AUTOSAR XML (schema 4-2-2)
package /Asw
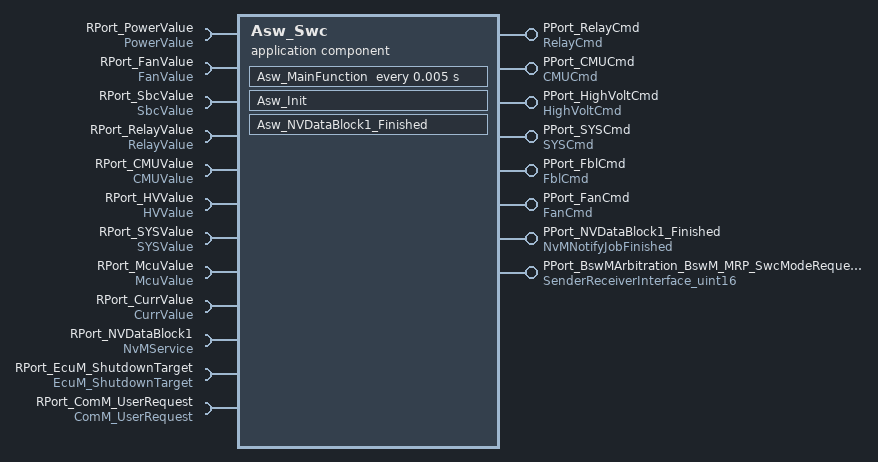
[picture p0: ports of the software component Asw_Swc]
  application sw component type Asw_Swc
    5 x provide port:
      PPort_RelayCmd: provided-interface=RelayCmd
      PPort_CMUCmd: provided-interface=CMUCmd
      PPort_HighVoltCmd: provided-interface=HighVoltCmd
      PPort_SYSCmd: provided-interface=SYSCmd
      PPort_FblCmd: provided-interface=FblCmd
    9 x require port:
      RPort_PowerValue: required-interface=PowerValue
      RPort_FanValue: required-interface=FanValue
      RPort_SbcValue: required-interface=SbcValue
      RPort_RelayValue: required-interface=RelayValue
      RPort_CMUValue: required-interface=CMUValue
      RPort_HVValue: required-interface=HVValue
      RPort_SYSValue: required-interface=SYSValue
      RPort_McuValue: required-interface=McuValue
      RPort_CurrValue: required-interface=CurrValue
    provide port PPort_FanCmd: provided-interface=FanCmd
    provide port PPort_NVDataBlock1_Finished: provided-interface=NvMNotifyJobFinished
    require port RPort_NVDataBlock1: required-interface=NvMService
    provide port PPort_BswMArbitration_BswM_MRP_SwcModeRequest: provided-interface=SenderReceiverInterface_uint16
    require port RPort_EcuM_ShutdownTarget: required-interface=EcuM_ShutdownTarget
    require port RPort_ComM_UserRequest: required-interface=ComM_UserRequest
    behavior SwcInternalBehavior: data-type-mapping=ComMModeMapping
      timing event TE_Asw_MainFunction_5ms: start-on-event=Asw_MainFunction, period=0.005
      operation invoked event OE_Asw_NVDataBlock1_Finished: start-on-event=Asw_NVDataBlock1_Finished, operation=PPort_NVDataBlock1_Finished.JobFinished
      runnable Asw_MainFunction
        data-receive-point-by-arguments:
          31 x access:
            DRPA_KL30Volt_V_0: accessed-variable=RPort_PowerValue.KL30Volt_V
            DRPA_KL30VoltVld_flg_0: accessed-variable=RPort_PowerValue.KL30VoltVld_flg
            DRPA_BSWInitFinish_flg_0: accessed-variable=RPort_McuValue.BSWInitFinish_flg
            DRPA_KL15WakeupState_flg_0: accessed-variable=RPort_SbcValue.KL15WakeupState_flg
            DRPA_BMULastPwrDownState_0: accessed-variable=RPort_SbcValue.BMULastPwrDownState
            DRPA_VoltA_V_0: accessed-variable=RPort_HVValue.VoltA_V
            DRPA_VoltAVld_flg_0: accessed-variable=RPort_HVValue.VoltAVld_flg
            DRPA_VoltB_V_0: accessed-variable=RPort_HVValue.VoltB_V
            DRPA_VoltBVld_flg_0: accessed-variable=RPort_HVValue.VoltBVld_flg
            DRPA_VoltC_V_0: accessed-variable=RPort_HVValue.VoltC_V
            DRPA_VoltCVld_flg_0: accessed-variable=RPort_HVValue.VoltCVld_flg
            DRPA_BSWRequestReset_flg_0: accessed-variable=RPort_SYSValue.BSWRequestReset_flg
            DRPA_PackCurr_A_0: accessed-variable=RPort_CurrValue.PackCurr_A
            DRPA_PackCurrVld_flg_0: accessed-variable=RPort_CurrValue.PackCurrVld_flg
            DRPA_GlobalHCtrState_flg_0: accessed-variable=RPort_RelayValue.GlobalHCtrState_flg
            DRPA_PosCtrCmdState_flg_0: accessed-variable=RPort_RelayValue.PosCtrCmdState_flg
            DRPA_CellBalState_flg_0: accessed-variable=RPort_CMUValue.CellBalState_flg
            DRPA_CellTemp1_C_0: accessed-variable=RPort_CMUValue.CellTemp1_C
            DRPA_CellTemp1Vld_flg_0: accessed-variable=RPort_CMUValue.CellTemp1Vld_flg
            DRPA_CellTemp2_C_0: accessed-variable=RPort_CMUValue.CellTemp2_C
            DRPA_CellTemp2Vld_flg_0: accessed-variable=RPort_CMUValue.CellTemp2Vld_flg
            DRPA_CMUPCBTemp1_C_0: accessed-variable=RPort_CMUValue.CMUPCBTemp1_C
            DRPA_CMUPCBTemp1Vld_flg_0: accessed-variable=RPort_CMUValue.CMUPCBTemp1Vld_flg
            DRPA_CMUPCBTemp2_C_0: accessed-variable=RPort_CMUValue.CMUPCBTemp2_C
            DRPA_CMUPCBTemp2Vld_flg_0: accessed-variable=RPort_CMUValue.CMUPCBTemp2Vld_flg
            DRPA_CellVolt_mV_0: accessed-variable=RPort_CMUValue.CellVolt_mV
            DRPA_CellVoltVld_flg_0: accessed-variable=RPort_CMUValue.CellVoltVld_flg
            DRPA_CellComErr_flg_0: accessed-variable=RPort_CMUValue.CellComErr_flg
            DRPA_CellOpenErr_flg_0: accessed-variable=RPort_CMUValue.CellOpenErr_flg
            DRPA_CellMeasCmd_flg_0: accessed-variable=RPort_CMUValue.CellMeasCmd_flg
            DRPA_FeedbackVolt_V_0: accessed-variable=RPort_FanValue.FeedbackVolt_V
        data-send-points:
          9 x access:
            DSP_GlobalHCtrCmd_flg_0: accessed-variable=PPort_RelayCmd.GlobalHCtrCmd_flg
            DSP_PosCtrCmd_flg_0: accessed-variable=PPort_RelayCmd.PosCtrCmd_flg
            DSP_OutFanPWMFrq_Hz_0: accessed-variable=PPort_FanCmd.OutFanPWMFrq_Hz
            DSP_OutFanDuty_pct_0: accessed-variable=PPort_FanCmd.OutFanDuty_pct
            DSP_RadyToSleep_flg_0: accessed-variable=PPort_SYSCmd.RadyToSleep_flg
            DSP_FBLForbid_flg_0: accessed-variable=PPort_FblCmd.FBLForbid_flg
            DSP_CellBalCmd_flg_0: accessed-variable=PPort_CMUCmd.CellBalCmd_flg
            DSP_PackVoltMeasCmd_flg_0: accessed-variable=PPort_HighVoltCmd.PackVoltMeasCmd_flg
            DSP_VDP_uint16_0: accessed-variable=PPort_BswMArbitration_BswM_MRP_SwcModeRequest.VDP_uint16
        4 x sync call:
          SynchronousServerCallPoint_1: operation=RPort_NVDataBlock1.WriteBlock
          SynchronousServerCallPoint_0: operation=RPort_NVDataBlock1.SetRamBlockStatus
          SynchronousServerCallPoint_2: operation=RPort_EcuM_ShutdownTarget.SelectShutdownTarget
          SynchronousServerCallPoint_3: operation=RPort_ComM_UserRequest.GetCurrentComMode
      runnable Asw_Init
      runnable Asw_NVDataBlock1_Finished
